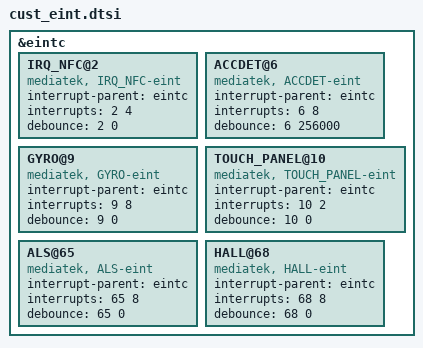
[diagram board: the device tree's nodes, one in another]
/*
 * Generated by MTK SP DrvGen Version 03.13.6 for MT6753. Copyright MediaTek Inc. (C) 2013.
 * Fri Nov 27 11:11:52 2015
 * Do Not Modify the File.
 */

/*************************
 * EINT DTSI File
*************************/

&eintc {
	IRQ_NFC@2 {
		compatible = "mediatek, IRQ_NFC-eint";
		interrupt-parent = <&eintc>;
		interrupts = <2 4>;
		debounce = <2 0>;
	};

	ACCDET@6 {
		compatible = "mediatek, ACCDET-eint";
		interrupt-parent = <&eintc>;
		interrupts = <6 8>;
		debounce = <6 256000>;
	};

	GYRO@9 {
		compatible = "mediatek, GYRO-eint";
		interrupt-parent = <&eintc>;
		interrupts = <9 8>;
		debounce = <9 0>;
	};

	TOUCH_PANEL@10 {
		compatible = "mediatek, TOUCH_PANEL-eint";
		interrupt-parent = <&eintc>;
		interrupts = <10 2>;
		debounce = <10 0>;
	};

	ALS@65 {
		compatible = "mediatek, ALS-eint";
		interrupt-parent = <&eintc>;
		interrupts = <65 8>;
		debounce = <65 0>;
	};

	HALL@68 {
		compatible = "mediatek, HALL-eint";
		interrupt-parent = <&eintc>;
		interrupts = <68 8>;
		debounce = <68 0>;
	};

};
